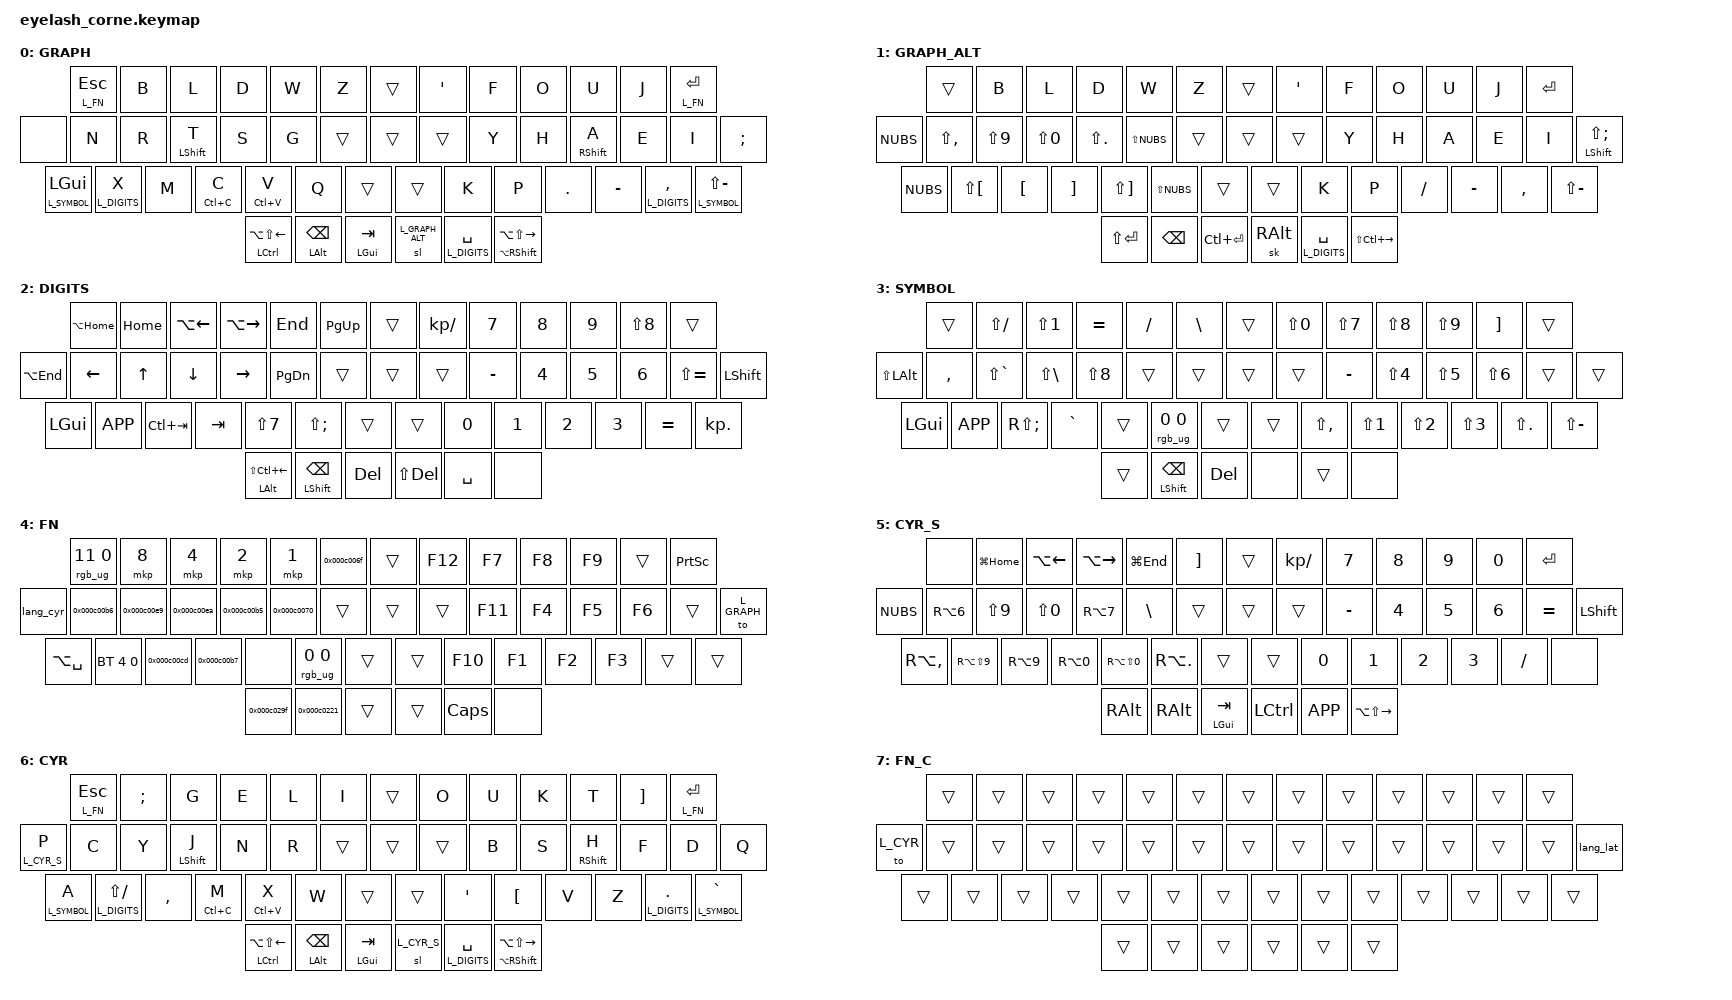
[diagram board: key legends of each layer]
/*
 * Згенеровано layout_dev_project/scripts/zmk/keymap_from_dump.py з дампу
 * клавіатури (ZMK Studio). Шари в порядку id; порядок Studio — у
 * налаштуваннях клавіатури.
 */

#include <behaviors.dtsi>
#include <dt-bindings/zmk/keys.h>
#include <dt-bindings/zmk/bt.h>

#define L_GRAPH      0
#define L_GRAPH_ALT  1
#define L_DIGITS     2
#define L_SYMBOL     3
#define L_FN         4
#define L_CYR_S      5
#define L_CYR        6
#define L_FN_C       7

/ {
    behaviors {
        /* Tap = ESC, Hold = FN layer */
        esc_fn: esc_fn {
            compatible = "zmk,behavior-hold-tap";
            #binding-cells = <2>;
            tapping-term-ms = <200>;
            flavor = "balanced";
            bindings = <&kp>, <&mo>;
        };

        /* Home-row mods: холд лише якщо наступна клавіша на іншій руці / тхамбі
         * (перекат однією рукою = завжди тап) і лише після паузи в друці. */
        hml: home_row_mod_left {
            compatible = "zmk,behavior-hold-tap";
            display-name = "HRM Left";
            #binding-cells = <2>;
            flavor = "balanced";
            tapping-term-ms = <280>;
            quick-tap-ms = <175>;
            require-prior-idle-ms = <150>;
            hold-trigger-key-positions = <7 8 9 10 11 12 22 23 24 25 26 27 36 37 38 39 40 41 42 43 44 45 46 47>;
            hold-trigger-on-release;
            bindings = <&kp>, <&kp>;
        };

        hmr: home_row_mod_right {
            compatible = "zmk,behavior-hold-tap";
            display-name = "HRM Right";
            #binding-cells = <2>;
            flavor = "balanced";
            tapping-term-ms = <280>;
            quick-tap-ms = <175>;
            require-prior-idle-ms = <150>;
            hold-trigger-key-positions = <0 1 2 3 4 5 13 14 15 16 17 18 28 29 30 31 32 33 42 43 44 45 46 47>;
            hold-trigger-on-release;
            bindings = <&kp>, <&kp>;
        };

        /* Кирилиця (ua): тап ",", Shift+тап "." (шифт маскується, xkb ua дає
         * "." на голій FSLH). Стандарт ЙЦУКЕН навпаки — кома частіша. 2026-10-30. */
        ua_comma_dot: ua_comma_dot {
            compatible = "zmk,behavior-mod-morph";
            #binding-cells = <0>;
            bindings = <&kp LS(FSLH)>, <&kp FSLH>;
            mods = <(MOD_LSFT|MOD_RSFT)>;
        };

        /* Кома-крапка з холдом шару (як &lt): &lt_cd ШАР 0 */
        lt_cd: layer_tap_comma_dot {
            compatible = "zmk,behavior-hold-tap";
            display-name = "LT Comma/Dot";
            #binding-cells = <2>;
            flavor = "tap-preferred";
            tapping-term-ms = <200>;
            bindings = <&mo>, <&ua_comma_dot>;
        };

        /* Латиниця (us): тап ":", Shift+тап ";". 2026-10-30. */
        colon_semi: colon_semi {
            compatible = "zmk,behavior-mod-morph";
            display-name = "Colon/Semi";
            #binding-cells = <0>;
            bindings = <&kp LS(SEMI)>, <&kp SEMI>;
            mods = <(MOD_LSFT|MOD_RSFT)>;
        };

    };

    macros {
        lang_tog: lang_toggle {
            compatible = "zmk,behavior-macro";
            display-name = "Lang Toggle";
            #binding-cells = <0>;
            bindings
                = <&tog L_CYR>
                , <&macro_press &kp LALT>
                , <&macro_tap &kp SPACE>
                , <&macro_release &kp LALT>
                ;
        };

        /* Мова ОС — перемикач Alt+Space (Linux: grp:alt_space_toggle; macOS:
         * Option+Space). Щоб шар і мова ОС не розходились, перемикач
         * надсилається лише тоді, коли мова справді змінюється: на FN (прийшли
         * з латиниці) Lang CYR = шар + Alt+Space, а →LAT — лише шар; на FN_C
         * (прийшли з кирилиці) навпаки. Розсинхрон (мову змінили мишкою) —
         * клавіша «Ресинк» на FN: лише Alt+Space. 2026-10-30. */
        lang_cyr: lang_cyr {
            compatible = "zmk,behavior-macro";
            display-name = "Lang CYR";
            #binding-cells = <0>;
            bindings = <&to L_CYR>, <&kp LA(SPACE)>;
        };

        lang_lat: lang_lat {
            compatible = "zmk,behavior-macro";
            display-name = "Lang LAT";
            #binding-cells = <0>;
            bindings = <&to L_GRAPH>, <&kp LA(SPACE)>;
        };

    };

    keymap {
        compatible = "zmk,keymap";

        layer_graph {
            display-name = "GRAPH";
            bindings = <
                /* верх */ &lt L_FN ESC  &kp B  &kp L  &kp D  &kp W  &kp Z  &trans  &kp SQT  &kp F  &kp O  &kp U  &kp J  &lt L_FN RET
                /* дім */ &none  &kp N  &kp R  &hml LSHFT T  &kp S  &kp G  &trans  &trans  &trans  &kp Y  &kp H  &hmr RSHFT A  &kp E  &kp I  &kp SEMI
                /* низ */ &lt L_SYMBOL LGUI  &lt L_DIGITS X  &kp M  &hml LC(C) C  &hml LC(V) V  &kp Q  &trans  &trans  &kp K  &kp P  &kp DOT  &kp MINUS  &lt L_DIGITS COMMA  &lt L_SYMBOL LS(MINUS)
                /* тхамби */ &mt LCTRL LA(LS(LEFT))  &mt LALT BSPC  &mt LGUI TAB  &sl L_GRAPH_ALT  &lt L_DIGITS SPACE  &mt LA(RSHFT) LA(LS(RIGHT))
            >;
        };

        layer_graph_alt {
            display-name = "GRAPH_ALT";
            bindings = <
                /* верх */ &trans  &kp B  &kp L  &kp D  &kp W  &kp Z  &trans  &kp SQT  &kp F  &kp O  &kp U  &kp J  &kp RET
                /* дім */ &kp NUBS  &kp LS(COMMA)  &kp LS(N9)  &kp LS(N0)  &kp LS(DOT)  &kp LS(NUBS)  &trans  &trans  &trans  &kp Y  &kp H  &kp A  &kp E  &kp I  &mt LSHFT LS(SEMI)
                /* низ */ &kp NUBS  &kp LS(LBKT)  &kp LBKT  &kp RBKT  &kp LS(RBKT)  &kp LS(NUBS)  &trans  &trans  &kp K  &kp P  &kp FSLH  &kp MINUS  &kp COMMA  &kp LS(MINUS)
                /* тхамби */ &kp LS(RET)  &kp BSPC  &kp LC(RET)  &sk RALT  &lt L_DIGITS SPACE  &kp LS(LC(RIGHT))
            >;
        };

        layer_digits {
            display-name = "DIGITS";
            bindings = <
                /* верх */ &kp LA(HOME)  &kp HOME  &kp LA(LEFT)  &kp LA(RIGHT)  &kp END  &kp PG_UP  &trans  &kp KP_SLASH  &kp N7  &kp N8  &kp N9  &kp LS(N8)  &trans
                /* дім */ &kp LA(END)  &kp LEFT  &kp UP  &kp DOWN  &kp RIGHT  &kp PG_DN  &trans  &trans  &trans  &kp MINUS  &kp N4  &kp N5  &kp N6  &kp LS(EQUAL)  &kp LSHFT
                /* низ */ &kp LGUI  &kp K_APP  &kp LC(TAB)  &kp TAB  &kp LS(N7)  &kp LS(SEMI)  &trans  &trans  &kp N0  &kp N1  &kp N2  &kp N3  &kp EQUAL  &kp KP_DOT
                /* тхамби */ &mt LALT LS(LC(LEFT))  &mt LSHFT BSPC  &kp DEL  &kp LS(DEL)  &kp SPACE  &none
            >;
        };

        layer_symbol {
            display-name = "SYMBOL";
            bindings = <
                /* верх */ &trans  &kp LS(FSLH)  &kp LS(N1)  &kp EQUAL  &kp FSLH  &kp BSLH  &trans  &kp LS(N0)  &kp LS(N7)  &kp LS(N8)  &kp LS(N9)  &kp RBKT  &trans
                /* дім */ &kp LS(LALT)  &kp COMMA  &kp LS(GRAVE)  &kp LS(BSLH)  &kp LS(N8)  &trans  &trans  &trans  &trans  &kp MINUS  &kp LS(N4)  &kp LS(N5)  &kp LS(N6)  &trans  &trans
                /* низ */ &kp LGUI  &kp K_APP  &kp RS(SEMI)  &kp GRAVE  &trans  &rgb_ug 0 0  &trans  &trans  &kp LS(COMMA)  &kp LS(N1)  &kp LS(N2)  &kp LS(N3)  &kp LS(DOT)  &kp LS(MINUS)
                /* тхамби */ &trans  &mt LSHFT BSPC  &kp DEL  &none  &trans  &none
            >;
        };

        layer_fn {
            display-name = "FN";
            bindings = <
                /* верх */ &rgb_ug 11 0  &mkp 8  &mkp 4  &mkp 2  &mkp 1  &kp 0x000c006f  &trans  &kp F12  &kp F7  &kp F8  &kp F9  &trans  &kp PSCRN
                /* дім */ &lang_cyr  &kp 0x000c00b6  &kp 0x000c00e9  &kp 0x000c00ea  &kp 0x000c00b5  &kp 0x000c0070  &trans  &trans  &trans  &kp F11  &kp F4  &kp F5  &kp F6  &trans  &to L_GRAPH
                /* низ */ &kp LA(SPACE)  &bt 4 0  &kp 0x000c00cd  &kp 0x000c00b7  &none  &rgb_ug 0 0  &trans  &trans  &kp F10  &kp F1  &kp F2  &kp F3  &trans  &trans
                /* тхамби */ &kp 0x000c029f  &kp 0x000c0221  &trans  &trans  &kp CAPS  &none
            >;
        };

        layer_cyr_s {
            display-name = "CYR_S";
            bindings = <
                /* верх */ &none  &kp LG(HOME)  &kp LA(LEFT)  &kp LA(RIGHT)  &kp LG(END)  &kp RBKT  &trans  &kp KP_SLASH  &kp N7  &kp N8  &kp N9  &kp N0  &kp RET
                /* дім */ &kp NUBS  &kp RA(N6)  &kp LS(N9)  &kp LS(N0)  &kp RA(N7)  &kp BSLH  &trans  &trans  &trans  &kp MINUS  &kp N4  &kp N5  &kp N6  &kp EQUAL  &kp LSHFT
                /* низ */ &kp RA(COMMA)  &kp RA(LS(N9))  &kp RA(N9)  &kp RA(N0)  &kp RA(LS(N0))  &kp RA(DOT)  &trans  &trans  &kp N0  &kp N1  &kp N2  &kp N3  &kp FSLH  &none
                /* тхамби */ &kp RALT  &kp RALT  &mt LGUI TAB  &kp LCTRL  &kp K_APP  &kp LA(LS(RIGHT))
            >;
        };

        layer_cyr {
            display-name = "CYR";
            bindings = <
                /* верх */ &lt L_FN ESC  &kp SEMI  &kp G  &kp E  &kp L  &kp I  &trans  &kp O  &kp U  &kp K  &kp T  &kp RBKT  &lt L_FN RET
                /* дім */ &lt L_CYR_S P  &kp C  &kp Y  &hml LSHFT J  &kp N  &kp R  &trans  &trans  &trans  &kp B  &kp S  &hmr RSHFT H  &kp F  &kp D  &kp Q
                /* низ */ &lt L_SYMBOL A  &lt L_DIGITS LS(FSLH)  &kp COMMA  &hml LC(C) M  &hml LC(V) X  &kp W  &trans  &trans  &kp SQT  &kp LBKT  &kp V  &kp Z  &lt L_DIGITS DOT  &lt L_SYMBOL GRAVE
                /* тхамби */ &mt LCTRL LA(LS(LEFT))  &mt LALT BSPC  &mt LGUI TAB  &sl L_CYR_S  &lt L_DIGITS SPACE  &mt LA(RSHFT) LA(LS(RIGHT))
            >;
        };

        /* Умовний: вмикається сам, коли активні CYR і FN (див. conditional_layers). */
        layer_fn_c {
            display-name = "FN_C";
            bindings = <
                /* верх */ &trans  &trans  &trans  &trans  &trans  &trans  &trans  &trans  &trans  &trans  &trans  &trans  &trans
                /* дім */ &to L_CYR  &trans  &trans  &trans  &trans  &trans  &trans  &trans  &trans  &trans  &trans  &trans  &trans  &trans  &lang_lat
                /* низ */ &trans  &trans  &trans  &trans  &trans  &trans  &trans  &trans  &trans  &trans  &trans  &trans  &trans  &trans
                /* тхамби */ &trans  &trans  &trans  &trans  &trans  &trans
            >;
        };
    };

    conditional_layers {
        compatible = "zmk,conditional-layers";
        fn_from_cyr {
            if-layers = <L_CYR L_FN>;
            then-layer = <L_FN_C>;
        };
    };
};
